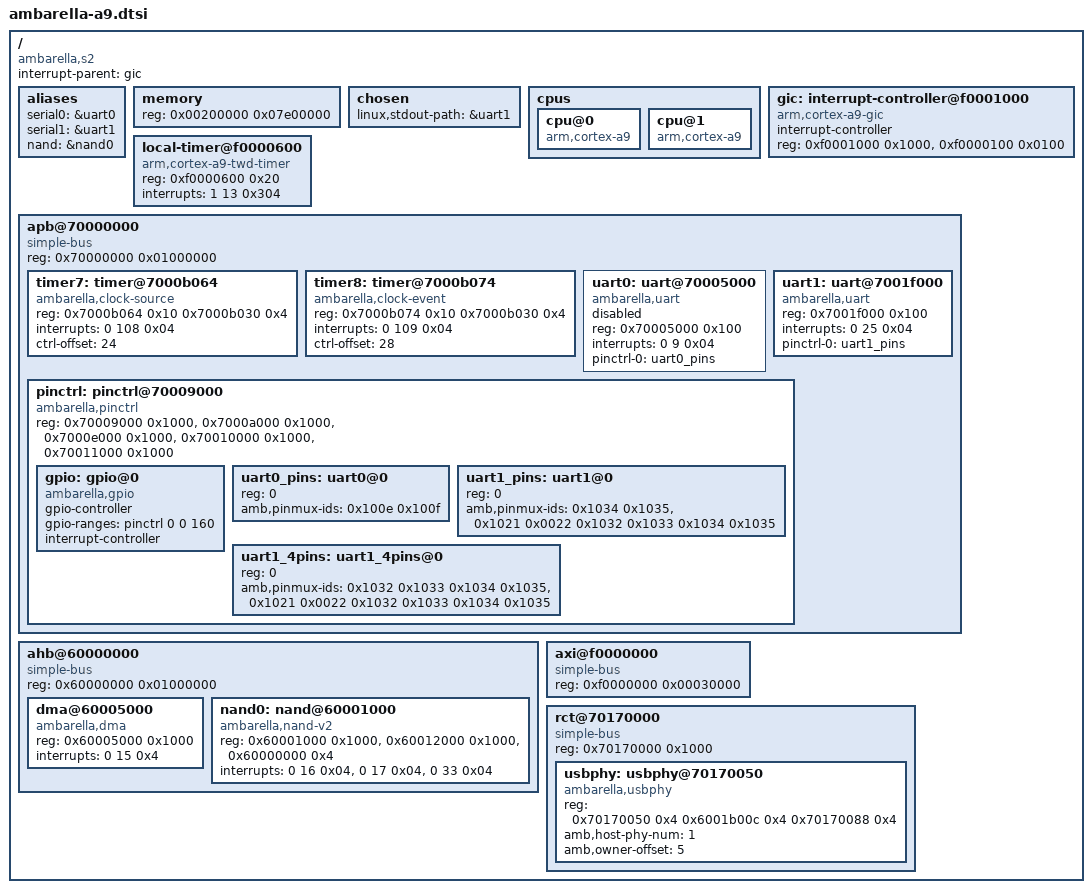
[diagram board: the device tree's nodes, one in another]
/*
 * Copyright (C) 2013 Ambarella,Inc. - http://www.ambarella.com/
 * Author: Cao Rongrong <rrcao@ambarella.com>
 *
 * This program is free software; you can redistribute it and/or modify
 * it under the terms of the GNU General Public License version 2 as
 * published by the Free Software Foundation.
 */

/include/ "skeleton.dtsi"

/ {
	compatible = "ambarella,s2";
	interrupt-parent = <&gic>;

	aliases {
		serial0 = &uart0;
		serial1 = &uart1;
		nand = &nand0;
	};

	/* the memory node will be overwritten in Amboot,
	 * here is just the default value. */
	memory {
		device_type = "memory";
		reg = <0x00200000 0x07e00000>; /* 126M */
	};

	chosen {
		linux,stdout-path = &uart1;
	};

	cpus {
		#address-cells = <1>;
		#size-cells = <0>;
		cpu@0 {
			compatible = "arm,cortex-a9";
		};
		cpu@1 {
			compatible = "arm,cortex-a9";
		};
	};

	gic: interrupt-controller@f0001000 {
		compatible = "arm,cortex-a9-gic";
		interrupt-controller;
		#interrupt-cells = <3>;
		reg = <0xf0001000 0x1000>,
			  <0xf0000100 0x0100>;
	};

	local-timer@f0000600 {
		compatible = "arm,cortex-a9-twd-timer";
		reg = <0xf0000600 0x20>;
		interrupts = <1 13 0x304>;
	};

	apb@70000000 {	/* APB */
		compatible = "simple-bus";
		#address-cells = <1>;
		#size-cells = <1>;
		reg = <0x70000000 0x01000000>;
		ranges;

		timer7: timer@7000b064 {
			compatible = "ambarella,clock-source";
			reg = <0x7000b064 0x10 0x7000b030 0x4>;
			interrupts = <0 108 0x04>;
			ctrl-offset = <24>; /* bit offset in timer-ctrl reg */
		};

		timer8: timer@7000b074 {
			compatible = "ambarella,clock-event";
			reg = <0x7000b074 0x10 0x7000b030 0x4>;
			interrupts = <0 109 0x04>;
			ctrl-offset = <28>; /* bit offset in timer-ctrl reg */
		};

		uart0: uart@70005000 {
			compatible = "ambarella,uart";
			reg = <0x70005000 0x100>;
			interrupts = <0 9 0x04>;
			pinctrl-names = "default";
			pinctrl-0 = <&uart0_pins>;
			status = "disable";
			/* amb,tx-fifo-fix; */
		};

		uart1: uart@7001f000 {
			compatible = "ambarella,uart";
			reg = <0x7001f000 0x100>;
			interrupts = <0 25 0x04>;
			pinctrl-names = "default";
			pinctrl-0 = <&uart1_pins>;
			status = "ok";
			/* amb,tx-fifo-fix; */
		};

		pinctrl: pinctrl@70009000 {
			compatible = "ambarella,pinctrl", "simple-bus";
			#address-cells = <1>;
			#size-cells = <0>;
			reg = <0x70009000 0x1000>,
			      <0x7000a000 0x1000>,
			      <0x7000e000 0x1000>,
			      <0x70010000 0x1000>,
			      <0x70011000 0x1000>;
			reg-names = "gpio0", "gpio1", "gpio2", "gpio3", "gpio4";
			#gpio-range-cells = <3>;

			gpio: gpio@0 {
				compatible = "ambarella,gpio";
				/* gpio interrupts to vic */
				/*
				interrupts = <0 10 0x04>,
					     <0 11 0x04>,
					     <0 30 0x04>,
					     <0 29 0x04>,
					     <0 48 0x04>;
				*/
				gpio-controller;
				#gpio-cells = <2>;
				gpio-ranges = <&pinctrl 0 0 160>;
				interrupt-controller;
				#interrupt-cells = <2>;
			};

			uart0_pins: uart0@0 {
				reg = <0>;
				amb,pinmux-ids = <0x100e 0x100f>;
			};

			uart1_pins: uart1@0 {
				reg = <0>;
				amb,pinmux-ids = <0x1034 0x1035>,
						 /* virtual pins, just for configuration purpose */
						 <0x1021 0x0022 0x1032 0x1033 0x1034 0x1035>;
			};

			uart1_4pins: uart1_4pins@0 {
				reg = <0>;
				amb,pinmux-ids = <0x1032 0x1033 0x1034 0x1035>,
						 /* virtual pins, just for configuration purpose */
						 <0x1021 0x0022 0x1032 0x1033 0x1034 0x1035>;
			};

		};
	};

	ahb@60000000 {	/* AHB */
		compatible = "simple-bus";
		#address-cells = <1>;
		#size-cells = <1>;
		reg = <0x60000000 0x01000000>;
		ranges;

		dma@60005000 {
			compatible = "ambarella,dma";
			reg = <0x60005000 0x1000>;
			interrupts = <0 15 0x4>;
		};

		nand0: nand@60001000 {
			compatible = "ambarella,nand-v2";
			reg = <0x60001000 0x1000>, /* fio reg address */
			      <0x60012000 0x1000>, /* fdma reg address */
			      <0x60000000 0x4>;    /* fifo base */
			interrupts = <0 16 0x04>,	/* fio_cmd_irq */
				     <0 17 0x04>,	/* fio_dma_irq */
				     <0 33 0x04>;	/* fdma_irq */
		};

	};

	axi@f0000000 {	/* AXI */
		compatible = "simple-bus";
		#address-cells = <1>;
		#size-cells = <1>;
		reg = <0xf0000000 0x00030000>;
		ranges;
	};

	rct@70170000 {
		compatible = "simple-bus";
		#address-cells = <1>;
		#size-cells = <1>;
		reg = <0x70170000 0x1000>;
		ranges;

		usbphy: usbphy@70170050 {
			compatible = "ambarella,usbphy";
			reg = <0x70170050 0x4 0x6001b00c 0x4 0x70170088 0x4>;
			amb,host-phy-num = <1>;
			amb,owner-offset = <5>;
		};
	};
};
